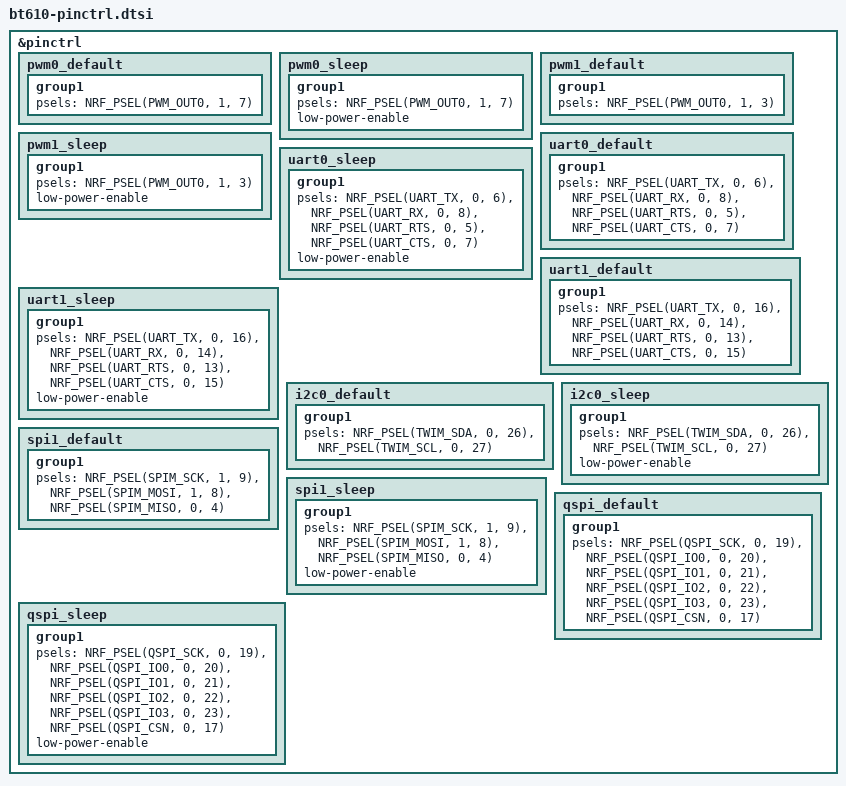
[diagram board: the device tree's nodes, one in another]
/*
 * Copyright (c) 2022 Nordic Semiconductor
 * SPDX-License-Identifier: Apache-2.0
 */

&pinctrl {
	pwm0_default: pwm0_default {
		group1 {
			psels = <NRF_PSEL(PWM_OUT0, 1, 7)>;
		};
	};

	pwm0_sleep: pwm0_sleep {
		group1 {
			psels = <NRF_PSEL(PWM_OUT0, 1, 7)>;
			low-power-enable;
		};
	};

	pwm1_default: pwm1_default {
		group1 {
			psels = <NRF_PSEL(PWM_OUT0, 1, 3)>;
		};
	};

	pwm1_sleep: pwm1_sleep {
		group1 {
			psels = <NRF_PSEL(PWM_OUT0, 1, 3)>;
			low-power-enable;
		};
	};

	uart0_default: uart0_default {
		group1 {
			psels = <NRF_PSEL(UART_TX, 0, 6)>,
				<NRF_PSEL(UART_RX, 0, 8)>,
				<NRF_PSEL(UART_RTS, 0, 5)>,
				<NRF_PSEL(UART_CTS, 0, 7)>;
		};
	};

	uart0_sleep: uart0_sleep {
		group1 {
			psels = <NRF_PSEL(UART_TX, 0, 6)>,
				<NRF_PSEL(UART_RX, 0, 8)>,
				<NRF_PSEL(UART_RTS, 0, 5)>,
				<NRF_PSEL(UART_CTS, 0, 7)>;
			low-power-enable;
		};
	};

	uart1_default: uart1_default {
		group1 {
			psels = <NRF_PSEL(UART_TX, 0, 16)>,
				<NRF_PSEL(UART_RX, 0, 14)>,
				<NRF_PSEL(UART_RTS, 0, 13)>,
				<NRF_PSEL(UART_CTS, 0, 15)>;
		};
	};

	uart1_sleep: uart1_sleep {
		group1 {
			psels = <NRF_PSEL(UART_TX, 0, 16)>,
				<NRF_PSEL(UART_RX, 0, 14)>,
				<NRF_PSEL(UART_RTS, 0, 13)>,
				<NRF_PSEL(UART_CTS, 0, 15)>;
			low-power-enable;
		};
	};

	i2c0_default: i2c0_default {
		group1 {
			psels = <NRF_PSEL(TWIM_SDA, 0, 26)>,
				<NRF_PSEL(TWIM_SCL, 0, 27)>;
		};
	};

	i2c0_sleep: i2c0_sleep {
		group1 {
			psels = <NRF_PSEL(TWIM_SDA, 0, 26)>,
				<NRF_PSEL(TWIM_SCL, 0, 27)>;
			low-power-enable;
		};
	};

	spi1_default: spi1_default {
		group1 {
			psels = <NRF_PSEL(SPIM_SCK, 1, 9)>,
				<NRF_PSEL(SPIM_MOSI, 1, 8)>,
				<NRF_PSEL(SPIM_MISO, 0, 4)>;
		};
	};

	spi1_sleep: spi1_sleep {
		group1 {
			psels = <NRF_PSEL(SPIM_SCK, 1, 9)>,
				<NRF_PSEL(SPIM_MOSI, 1, 8)>,
				<NRF_PSEL(SPIM_MISO, 0, 4)>;
			low-power-enable;
		};
	};

	qspi_default: qspi_default {
		group1 {
			psels = <NRF_PSEL(QSPI_SCK, 0, 19)>,
				<NRF_PSEL(QSPI_IO0, 0, 20)>,
				<NRF_PSEL(QSPI_IO1, 0, 21)>,
				<NRF_PSEL(QSPI_IO2, 0, 22)>,
				<NRF_PSEL(QSPI_IO3, 0, 23)>,
				<NRF_PSEL(QSPI_CSN, 0, 17)>;
		};
	};

	qspi_sleep: qspi_sleep {
		group1 {
			psels = <NRF_PSEL(QSPI_SCK, 0, 19)>,
				<NRF_PSEL(QSPI_IO0, 0, 20)>,
				<NRF_PSEL(QSPI_IO1, 0, 21)>,
				<NRF_PSEL(QSPI_IO2, 0, 22)>,
				<NRF_PSEL(QSPI_IO3, 0, 23)>,
				<NRF_PSEL(QSPI_CSN, 0, 17)>;
			low-power-enable;
		};
	};

};
